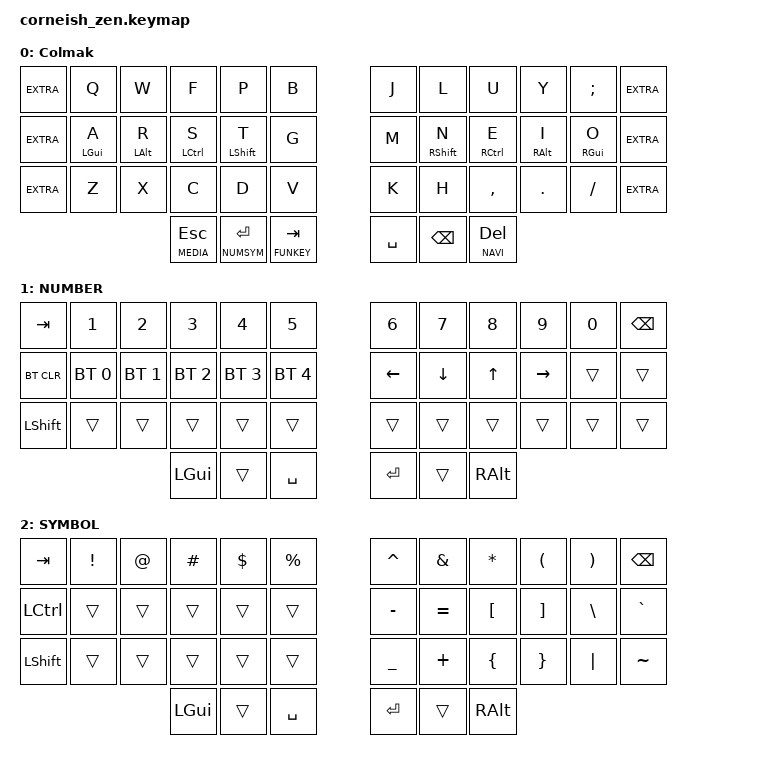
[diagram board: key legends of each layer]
#include <behaviors.dtsi>
#include <dt-bindings/zmk/keys.h>
#include <dt-bindings/zmk/bt.h>

/ {
  chosen {
    zmk,matrix_transform = &default_transform;
    //zmk,matrix_transform = &five_column_transform;
  };
};

/ {
        keymap {
                compatible = "zmk,keymap";


          // CM: this config is from sam; i can't use the default because
          // i only have 5 keys per side
          default_layer {
             label = "Colmak";
             bindings = <
                  <<<EXTRA>>>     &kp      Q &kp      W &kp       F    &kp        P    &kp B              &kp J          &kp        L    &kp        U &kp      Y &kp   SEMI    <<<EXTRA>>>
                  <<<EXTRA>>>     &hm LGUI A &hm LALT R &hm LCTRL S    &hm LSHIFT T    &kp G              &kp M          &hm RSHIFT N    &hm  RCTRL E &hm RALT I &hm RGUI O    <<<EXTRA>>>
                  <<<EXTRA>>>     &kp      Z &kp      X &kp       C    &kp        D    &kp V              &kp K          &kp        H    &kp     CMMA &kp    DOT &kp   FSLH    <<<EXTRA>>>
                                                  &lt MEDIA ESC  &lt NUMSYM RET  &lt FUNKEY TAB     &kp       SPC  &kp       BSPC  &lt NAVI DEL
             >;
         };

/* // CM: this was the default from zmk-config
                default_layer {
                        label = "QWERTY";
// -----------------------------------------------------------------------------------------
// |  TAB |  Q  |  W  |  E  |  R  |  T  |   |  Y  |  U   |  I  |  O  |  P  | BKSP |
// | CTRL |  A  |  S  |  D  |  F  |  G  |   |  H  |  J   |  K  |  L  |  ;  |  '   |
// | SHFT |  Z  |  X  |  C  |  V  |  B  |   |  N  |  M   |  ,  |  .  |  /  | ESC  |
//                    | GUI | LWR | SPC |   | ENT | RSE  | ALT |
                        bindings = <
   &kp TAB   &kp Q &kp W &kp E &kp R &kp T   &kp Y &kp U  &kp I     &kp O   &kp P    &kp BSPC
   &kp LCTRL &kp A &kp S &kp D &kp F &kp G   &kp H &kp J  &kp K     &kp L   &kp SEMI &kp SQT
   &kp LSHFT &kp Z &kp X &kp C &kp V &kp B   &kp N &kp M  &kp COMMA &kp DOT &kp FSLH &kp ESC
                  &kp LGUI &mo 1 &kp SPACE   &kp RET &mo 2 &kp RALT
                        >;
                };
*/

                lower_layer {
                        label = "NUMBER";
// -----------------------------------------------------------------------------------------
// |  TAB |  1  |  2  |  3  |  4  |  5  |   |  6  |  7  |  8  |  9  |  0  | BKSP |
// | BTCLR| BT1 | BT2 | BT3 | BT4 | BT5 |   | LFT | DWN |  UP | RGT |     |      |
// | SHFT |     |     |     |     |     |   |     |     |     |     |     |      |
//                    | GUI |     | SPC |   | ENT |     | ALT |
                        bindings = <
   &kp TAB    &kp N1       &kp N2       &kp N3       &kp N4       &kp N5         &kp N6   &kp N7   &kp N8 &kp N9    &kp N0 &kp BSPC
   &bt BT_CLR &bt BT_SEL 0 &bt BT_SEL 1 &bt BT_SEL 2 &bt BT_SEL 3 &bt BT_SEL 4   &kp LEFT &kp DOWN &kp UP &kp RIGHT &trans &trans
   &kp LSHFT  &trans       &trans       &trans       &trans       &trans         &trans   &trans   &trans &trans    &trans &trans
                          	        &kp LGUI     &trans       &kp SPACE      &kp RET  &trans   &kp RALT
                        >;
                };

                raise_layer {
                        label = "SYMBOL";
// -----------------------------------------------------------------------------------------
// |  TAB |  !  |  @  |  #  |  $  |  %  |   |  ^  |  &  |  *  |  (  |  )  | BKSP |
// | CTRL |  =  |     |     |     |     |   |  -  |  =  |  [  |  ]  |  \  |  `   |
// | SHFT |     |     |     |     |     |   |  _  |  +  |  {  |  }  | "|" |  ~   |
//                    | GUI |     | SPC |   | ENT |     | ALT |
                        bindings = <
   &kp  TAB  &kp EXCL &kp AT &kp HASH &kp DLLR &kp PRCNT   &kp CARET &kp AMPS  &kp STAR &kp LPAR &kp RPAR &kp BSPC
   &kp LCTRL &trans   &trans &trans   &trans   &trans      &kp MINUS &kp EQUAL &kp LBKT &kp RBKT &kp BSLH &kp GRAVE
   &kp LSHFT &trans   &trans &trans   &trans   &trans      &kp UNDER &kp PLUS  &kp LBRC &kp RBRC &kp PIPE &kp TILDE
                    	     &kp LGUI &trans   &kp SPACE   &kp RET   &trans    &kp RALT
                        >;
                };
        };
};
